# F28x7x_ipc_regs_cpu1 register map
Vendor: Texas Instruments
Peripheral module from a debugger description file (folder C2000).
Address unit: 16 bits
Registers are 32-bit, read-write, no defined reset value unless marked. A register's access mark holds for its fields unless they carry their own. Offsets are as the file gives them; lines under a group give offsets from that group; [hi:lo] are bit positions; {n}, {i} and the like mark numbered series; 'fields as' and 'values as' point back to an identical list; <NAME> marks a mode.

## IPC_REGS_CPU1 — IPC CPU1 Registers
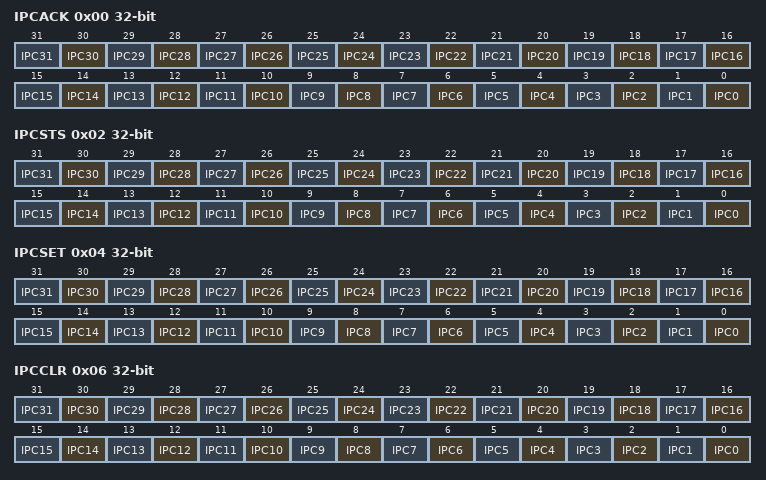
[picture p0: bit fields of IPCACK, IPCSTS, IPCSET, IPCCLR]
0x00 IPCACK — IPC incoming flag clear (acknowledge) register
  [n] IPC{n} (n=0..31) — Local IPC Flag {n} AcknowledgementLocal IPC Flag {n} Acknowledgement
0x02 IPCSTS — IPC incoming flag status register
  [n] IPC{n} (n=0..31) — Local IPC Flag {n} StatusLocal IPC Flag {n} Status
0x04 IPCSET — IPC remote flag set register
  [n] IPC{n} (n=0..31) — Set Remote IPC{n} FlagSet Remote IPC{n} Flag
0x06 IPCCLR — IPC remote flag clear register
  [n] IPC{n} (n=0..31) — Clear Remote IPC{n} FlagClear Remote IPC{n} Flag
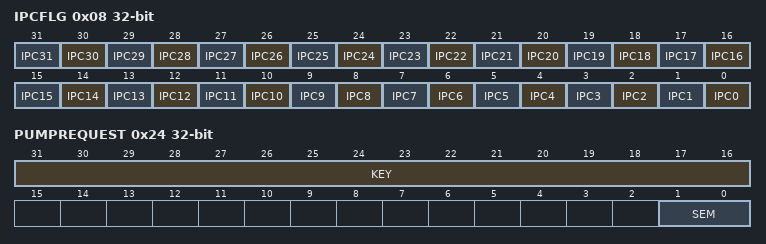
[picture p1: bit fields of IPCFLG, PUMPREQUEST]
0x08 IPCFLG — IPC remote flag status register
  [n] IPC{n} (n=0..31) — Remote IPC{n} Flag StatusRemote IPC{n} Flag Status
0x0C IPCCOUNTERL — IPC Counter Low Register
  [31:0] COUNT — IPC Counter's lower 32-bitIPC Counter's lower 32-bit
0x0E IPCCOUNTERH — IPC Counter High Register
  [31:0] COUNT — IPC Counter's upper 32-bitIPC Counter's upper 32-bit
0x10 IPCSENDCOM — Local to Remote IPC Command Register
  [31:0] COMMAND — Local to Remote IPC CommandLocal to Remote IPC Command
0x12 IPCSENDADDR — Local to Remote IPC Address Register
  [31:0] ADDRESS — Local to Remote IPC AddressLocal to Remote IPC Address
0x14 IPCSENDDATA — Local to Remote IPC Data Register
  [31:0] WDATA — Local to Remote IPC DataLocal to Remote IPC Data
0x16 IPCREMOTEREPLY — Remote to Local IPC Reply Data Register
  [31:0] RDATA — Remote to Local IPC Return DataRemote to Local IPC Return Data
0x18 IPCRECVCOM — Remote to Local IPC Command Register
  [31:0] COMMAND — Remote to Local IPC CommandRemote to Local IPC Command
0x1A IPCRECVADDR — Remote to Local IPC Address Register
  [31:0] ADDRESS — Remote to Local IPC AddressRemote to Local IPC Address
0x1C IPCRECVDATA — Remote to Local IPC Data Register
  [31:0] WDATA — Remote to Local IPC DataRemote to Local IPC Data
0x1E IPCLOCALREPLY — Local to Remote IPC Reply Data Register
  [31:0] RDATA — Local to Remote IPC Return DataLocal to Remote IPC Return Data
0x20 IPCBOOTSTS — CPU2 to CPU1 IPC Boot Status Register
  [31:0] BOOTSTS — CPU2 to CPU1 IPC Boot StatusCPU2 to CPU1 IPC Boot Status
0x22 IPCBOOTMODE — CPU1 to CPU2 IPC Boot Mode Register
  [31:0] BOOTMODE — CPU1 to CPU2 IPC Boot ModeCPU1 to CPU2 IPC Boot Mode
0x24 PUMPREQUEST — Flash programming semaphore PUMP request register
  [31:16] KEY — Key Qualifier for writes to this registerKey Qualifier for writes to this register
  [1:0] SEM — Flash Pump Request Semaphore between CPU1 and CPU2Flash Pump Request Semaphore between CPU1 and CPU2
